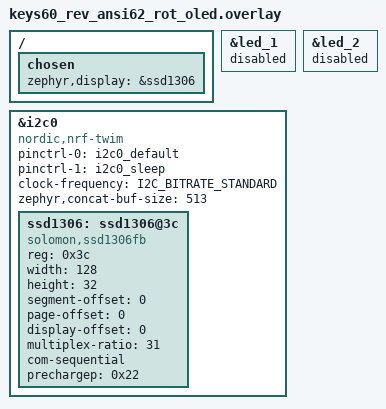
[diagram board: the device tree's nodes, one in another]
/*
 * Copyright (c) 2026 sig (Toxsig)
 *
 * SPDX-License-Identifier: MIT
 */

#include <zephyr/dt-bindings/i2c/i2c.h>
#include "keys60_rev_ansi62_rot.overlay"
#include "keys60_rev_ansi62_rot_oled-pinctrl.dtsi"

/ {
	chosen {
		zephyr,display = &ssd1306;
	};
};

/* Release the RGB LED pins for the OLED I2C bus. */
&led_1 {
	status = "disabled";
};

&led_2 {
	status = "disabled";
};

&i2c0 {
	compatible = "nordic,nrf-twim";
	status = "okay";
	pinctrl-0 = <&i2c0_default>;
	pinctrl-1 = <&i2c0_sleep>;
	pinctrl-names = "default", "sleep";
	clock-frequency = <I2C_BITRATE_STANDARD>;
	zephyr,concat-buf-size = <513>;

	ssd1306: ssd1306@3c {
		compatible = "solomon,ssd1306fb";
		reg = <0x3c>;
		width = <128>;
		height = <32>;
		segment-offset = <0>;
		page-offset = <0>;
		display-offset = <0>;
		multiplex-ratio = <31>;
		com-sequential;
		prechargep = <0x22>;
		status = "okay";
	};
};
